# STM32WBA50xx register map
File version: 1.0
Registers are 32-bit, read-write, reset 0x0 unless marked. A register's access mark holds for its fields unless they carry their own. Offsets are from the block's base; [hi:lo] are bit positions; {n}, {i} and the like mark numbered series; 'fields as' and 'values as' point back to an identical list.

## PWR — Power Control
Base 0x46020800
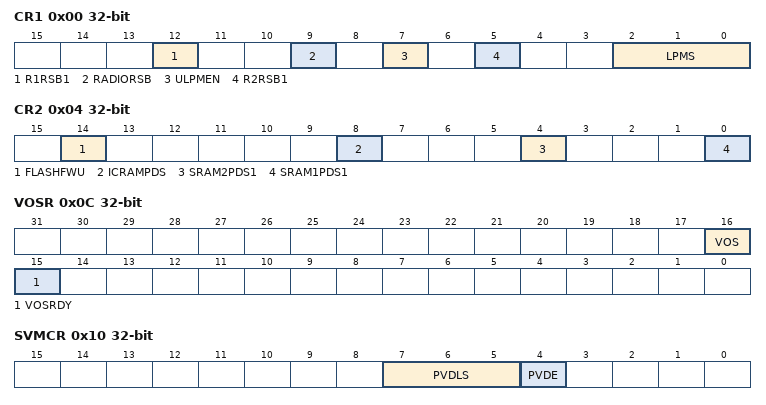
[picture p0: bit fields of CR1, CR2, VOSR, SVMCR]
0x00 CR1 — PWR power control register 1
  [12] R1RSB1 — SRAM1 Page 1 Retention in Standby
  [9] RADIORSB — 2.4GHz RADIO SRAMs (TXRX and Sequence) and Sleep clock retention in Standby mode
    0=NO_RETENTION (2.4 GHz RADIO SRAMs and sleep timer content not retained in Standby mode); 1=FULL_RETENTION (2.4 GHz RADIO SRAMs and sleep timer content retained in Standby mode)
  [7] ULPMEN — BOR ultra-low power mode in Standby/Shutdown
  [5] R2RSB1 — SRAM2 Retention in Standby
  [2:0] LPMS — LPMS[2:0] Low-power mode selection field
    0=STOP0 (Stop 0 mode); 1=STOP1 (Stop 1 mode); 4=STANDBY (Standby mode)
0x04 CR2 — PWR power control register 2
  [14] FLASHFWU — Flash low-power mode in Stop modes
  [8] ICRAMPDS — ICACHE SRAM power-down in Stop modes
    0=NO_RETENTION (ICACHE SRAM no retention in Stop mode); 1=FULL_RETENTION (ICACHE SRAM full retention in Stop mode)
  [4] SRAM2PDS1 — SRAM2 power-down in Stop modes
  [0] SRAM1PDS1 — SRAM1 Page 1 power-down in Stop modes
0x08 CR3 — PWR power control register 3
  [2] FSTEN — Fast soft start
0x0C VOSR — PWR voltage scaling register
  [16] VOS — Voltage scaling range selection
    1=SCALE1 (Voltage scaling range 1 (highest frequency)); 0=SCALE2 (Voltage scaling range 2 (lowest power))
  [15] VOSRDY — Ready bit for VCORE voltage scaling output selection
0x10 SVMCR — PWR supply voltage monitoring control register
  [7:5] PVDLS — PVDLS[2:0] Power voltage detector level selection field
    0=PVDLEVEL_0 (Voltage threshold detected by PVD 2.0 V); 1=PVDLEVEL_1 (Voltage threshold detected by PVD 2.2 V); 2=PVDLEVEL_2 (Voltage threshold detected by PVD 2.4 V); 3=PVDLEVEL_3 (Voltage threshold detected by PVD 2.5 V); 4=PVDLEVEL_4 (Voltage threshold detected by PVD 2.6 V); 5=PVDLEVEL_5 (Voltage threshold detected by PVD 2.8 V); 6=PVDLEVEL_6 (Voltage threshold detected by PVD 2.9 V); 7=PVDLEVEL_7
  [4] PVDE — Power voltage detector enable
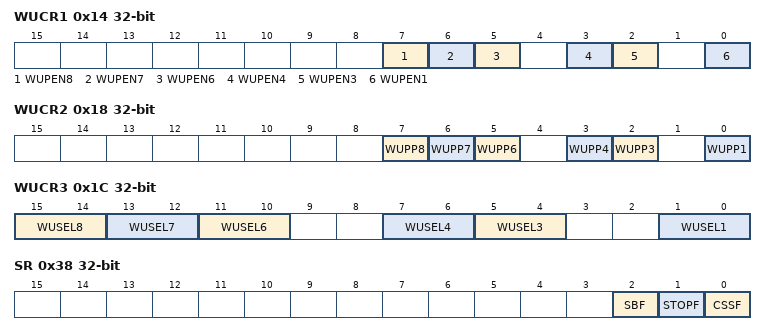
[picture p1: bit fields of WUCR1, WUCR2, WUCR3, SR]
0x14 WUCR1 — PWR wakeup control register 1
  [7] WUPEN8 — Wakeup pin WKUP8 enable
  [6] WUPEN7 — Wakeup pin WKUP7 enable
  [5] WUPEN6 — Wakeup pin WKUP6 enable
  [3] WUPEN4 — Wakeup pin WKUP4 enable
  [2] WUPEN3 — Wakeup pin WKUP3 enable
  [0] WUPEN1 — Wakeup pin WKUP1 enable
0x18 WUCR2 — PWR wakeup control register 2
  [7] WUPP8 — Wakeup pin WKUP8 polarity
  [6] WUPP7 — Wakeup pin WKUP7 polarity
  [5] WUPP6 — Wakeup pin WKUP6 polarity
  [3] WUPP4 — Wakeup pin WKUP4 polarity
  [2] WUPP3 — Wakeup pin WKUP3 polarity
  [0] WUPP1 — Wakeup pin WKUP1 polarity
0x1C WUCR3 — PWR wakeup control register 3
  [15:14] WUSEL8 — Wakeup pin WKUP8 selection field
  [13:12] WUSEL7 — Wakeup pin WKUP7 selection field
  [11:10] WUSEL6 — Wakeup pin WKUP6 selection field
  [7:6] WUSEL4 — Wakeup pin WKUP4 selection field
  [5:4] WUSEL3 — Wakeup pin WKUP3 selection field
  [1:0] WUSEL1 — Wakeup pin WKUP1 selection field
0x28 DBPR — PWR disable backup domain register
  [0] DBP — Disable backup domain write protection
0x38 SR — PWR status register
  [2] SBF — Standby/Shutdown flag
  [1] STOPF — Stop flag
  [0] CSSF — Clear Stop and Standby/Shutdown flags
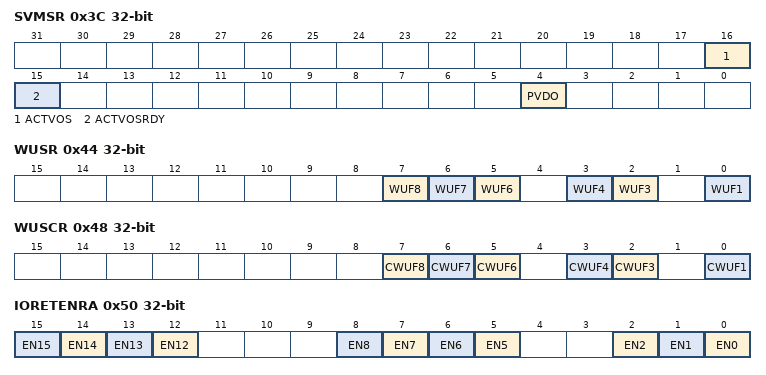
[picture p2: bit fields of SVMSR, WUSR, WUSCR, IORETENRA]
0x3C SVMSR — PWR supply voltage monitoring status register
  [16] ACTVOS — Voltage Output Scaling currently applied to VCORE
    values as VOSR.VOS
  [15] ACTVOSRDY — Voltage level ready for currently used VOS
  [4] PVDO — VDD voltage detector output
0x44 WUSR — PWR wakeup status register
  [7] WUF8 — Wakeup flag 8
  [6] WUF7 — Wakeup flag 7
  [5] WUF6 — Wakeup flag 6
  [3] WUF4 — Wakeup flag 4
  [2] WUF3 — Wakeup flag 3
  [0] WUF1 — Wakeup flag 1
0x44 WUSR_ALT (alternate view of WUSR) — PWR wakeup status register
  [7:0] WUF — all Wakeup flag
0x48 WUSCR — PWR wakeup status clear register
  [7] CWUF8 — Wakeup clear flag 8
  [6] CWUF7 — Wakeup clear flag 7
  [5] CWUF6 — Wakeup clear flag 6
  [3] CWUF4 — Wakeup clear flag 4
  [2] CWUF3 — Wakeup clear flag 3
  [0] CWUF1 — Wakeup clear flag 1
0x48 WUSCR_ALT (alternate view of WUSCR) — PWR wakeup status clear register
  [7:0] CWUF — all Wakeup clear flag
0x4C APCR — PWR apply pull configuration register
0x50 IORETENRA — PWR Port A IO retention in Standby register
  [n] EN{n} (n=12..15) — Standby GPIO retention enable for PA{n}
  [n] EN{n} (n=5..8) — Standby GPIO retention enable for PA{n}
  [2] EN2 — Standby GPIO retention enable for PA2
  [1] EN1 — Standby GPIO retention enable for PA1
  [0] EN0 — Standby GPIO retention enable for PA0
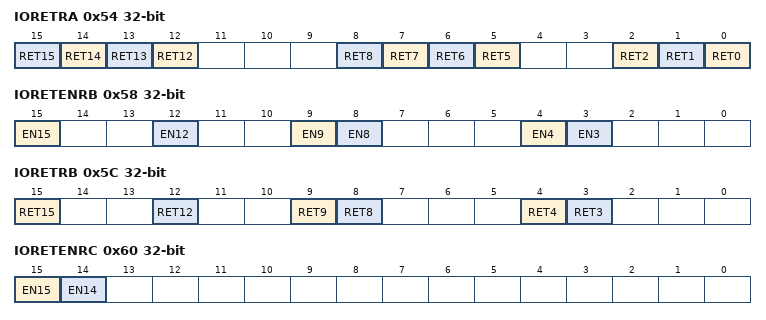
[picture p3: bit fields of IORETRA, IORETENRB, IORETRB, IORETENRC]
0x54 IORETRA — PWR Port A IO retention status in Standby register
  [n] RET{n} (n=12..15) — Standby GPIO retention status for PA{n}
  [n] RET{n} (n=5..8) — Standby GPIO retention status for PA{n}
  [2] RET2 — Standby GPIO retention status for PA2
  [1] RET1 — Standby GPIO retention status for PA1
  [0] RET0 — Standby GPIO retention status for PA0
0x58 IORETENRB — PWR Port B IO retention in Standby register
  [15] EN15 — Standby GPIO retention enable for PB15
  [12] EN12 — Standby GPIO retention enable for PB12
  [9] EN9 — Standby GPIO retention enable for PB9
  [8] EN8 — Standby GPIO retention enable for PB8
  [4] EN4 — Standby GPIO retention enable for PB4
  [3] EN3 — Standby GPIO retention enable for PB3
0x5C IORETRB — PWR Port B IO retention status in Standby register
  [15] RET15 — Standby GPIO retention status for PB15
  [12] RET12 — Standby GPIO retention status for PB12
  [9] RET9 — Standby GPIO retention status for PB9
  [8] RET8 — Standby GPIO retention status for PB8
  [4] RET4 — Standby GPIO retention status for PB4
  [3] RET3 — Standby GPIO retention status for PB3
0x60 IORETENRC — PWR Port C IO retention in Standby register
  [15] EN15 — Standby GPIO retention enable for PC15
  [14] EN14 — Standby GPIO retention enable for PC14
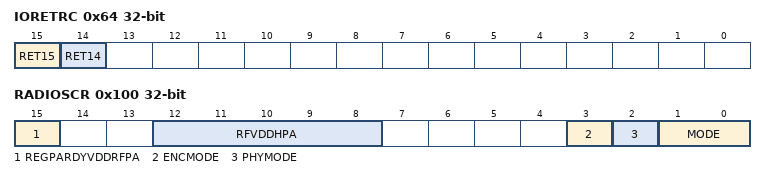
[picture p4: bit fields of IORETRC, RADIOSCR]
0x64 IORETRC — PWR Port C IO retention status in Standby register
  [15] RET15 — Standby GPIO retention status for PC15
  [14] RET14 — Standby GPIO retention status for PC14
0x88 IORETENRH — PWR Port H IO retention in Standby register
  [3] EN3 — Standby GPIO retention enable for PH3
0x8C IORETRH — PWR Port H IO retention status in Standby register
  [3] RET3 — Standby GPIO retention status for PH3
0x100 RADIOSCR — PWR 2.4 GHZ radio status and control register
  [15] REGPARDYVDDRFPA — Ready bit for VDDHPA voltage level when selecting VDDRFPA input
  [12:8] RFVDDHPA — 2.4 GHz RADIO VDDHPA control word
  [3] ENCMODE — 2.4 GHz RADIO encryption function operating mode
  [2] PHYMODE — 2.4 GHz RADIO PHY operating mode
    0=SLEEP_MODE (2.4 GHz RADIO Sleep mode); 1=STANDBY_MODE (2.4 GHz RADIO Standby mode)
  [1:0] MODE — 2.4 GHz RADIO operating mode
